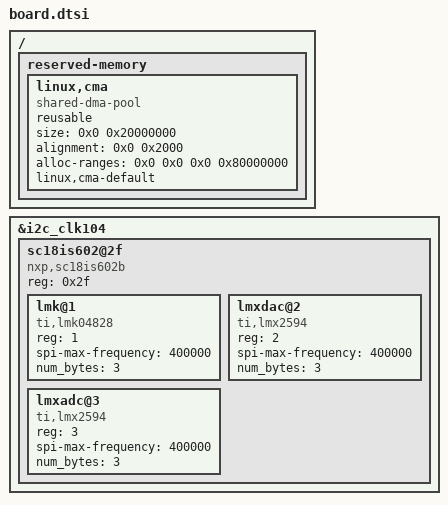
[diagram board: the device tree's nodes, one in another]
/* SPDX-License-Identifier: BSD-3-Clause
 * CLK104 and CMA wiring, following the upstream RFSoC-PYNQ EDF board ports.
 * Copyright (C) 2022 Xilinx, Inc.
 * Copyright (C) 2022-2026 Advanced Micro Devices, Inc.
 */
/ {
    reserved-memory {
        #address-cells = <2>;
        #size-cells = <2>;
        ranges;
        linux,cma {
            compatible = "shared-dma-pool";
            reusable;
            size = <0x0 0x20000000>;
            alignment = <0x0 0x2000>;
            alloc-ranges = <0x0 0x0 0x0 0x80000000>;
            linux,cma-default;
        };
    };
};
&i2c_clk104 {
    sc18is602@2f {
        compatible = "nxp,sc18is602b";
        reg = <0x2f>;
        #address-cells = <1>;
        #size-cells = <0>;
        lmk@1 {
            compatible = "ti,lmk04828";
            reg = <1>;
            spi-max-frequency = <400000>;
            num_bytes = <3>;
        };
        lmxdac@2 {
            compatible = "ti,lmx2594";
            reg = <2>;
            spi-max-frequency = <400000>;
            num_bytes = <3>;
        };
        lmxadc@3 {
            compatible = "ti,lmx2594";
            reg = <3>;
            spi-max-frequency = <400000>;
            num_bytes = <3>;
        };
    };
};
